# APM32F103xx register map
File version: 1.0
CPU: CM3 r2p1, little endian, no MPU, no FPU, 4 interrupt priority bits
Registers are 32-bit, read-write, reset 0x0 unless marked. A register's access mark holds for its fields unless they carry their own. Offsets are from the block's base; [hi:lo] are bit positions; {n}, {i} and the like mark numbered series; 'fields as' and 'values as' point back to an identical list.

## CRC — CRC calculation unit
Base 0x40023000
0x00 DATA reset 0xFFFFFFFF
0x04 INDATA — Independent Data register
  [7:0] INDATA
0x08 CTRL wo — Control register
  [0] RST — Reset bit

## FMC — Flash memory controller
Base 0x40022000
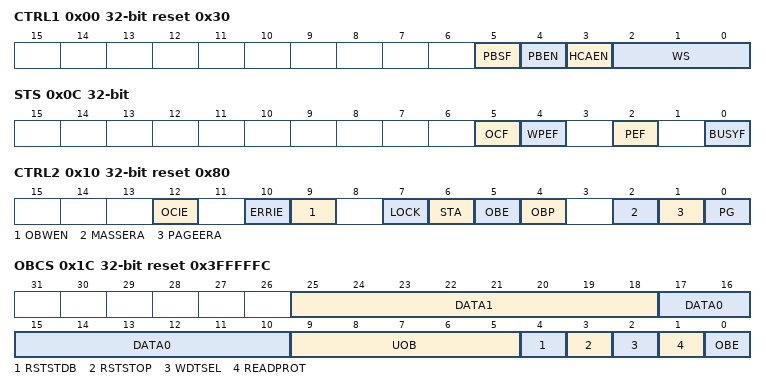
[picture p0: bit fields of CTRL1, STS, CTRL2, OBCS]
0x00 CTRL1 access per field reset 0x30 — Flash access control register
  [5] PBSF ro — Prefetch buffer status
  [4] PBEN rw — Prefetch buffer enable
  [3] HCAEN rw — Flash half cycle access enable
  [2:0] WS rw — Latency
0x04 KEY wo
  [31:0] KEY — FMC key
0x08 OBKEY wo — option byte key register
  [31:0] OBKEY — Option byte key
0x0C STS access per field — status register
  [5] OCF rw — End of operation
  [4] WPEF rw — Write protection error
  [2] PEF rw — Programming error
  [0] BUSYF ro — Busy
0x10 CTRL2 reset 0x80 — Control register
  [12] OCIE — End of operation interrupt enable
  [10] ERRIE — Error interrupt enable
  [9] OBWEN — Option bytes write enable
  [7] LOCK
  [6] STA — Start
  [5] OBE — Option byte erase
  [4] OBP — Option byte programming
  [2] MASSERA — Mass Erase
  [1] PAGEERA — Page Erase
  [0] PG — Programming
0x14 ADDR wo — Flash address register
  [31:0] ADDR — Flash Address
0x1C OBCS ro reset 0x3FFFFFC — Option byte register
  [25:18] DATA1
  [17:10] DATA0 — Data1
  [9:5] UOB
  [4] RSTSTDB — nRST_STDBY
  [3] RSTSTOP — nRST_STOP
  [2] WDTSEL
  [1] READPROT — Read protection
  [0] OBE — Option byte error
0x20 WRTPROT ro reset 0xFFFFFFFF — Write protection register
  [31:0] WRTPROT — Write protect

## DMA1 — DMA1 controller
Base 0x40020000
Same registers: DMA2 0x40020400
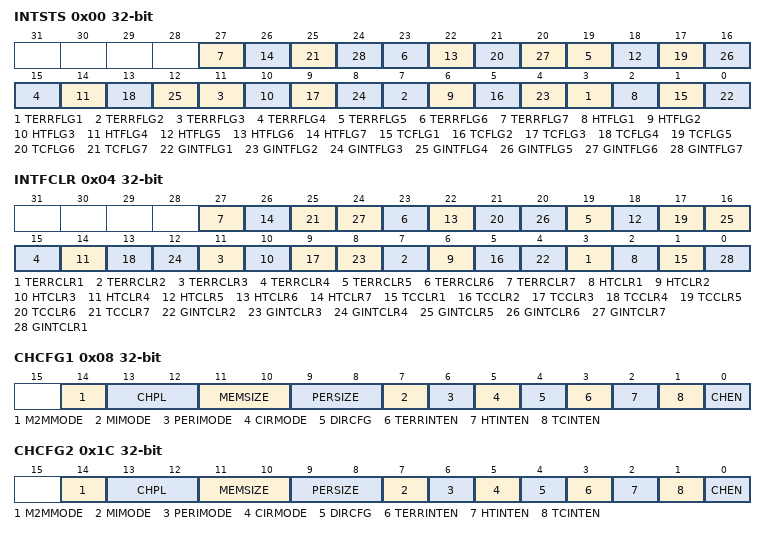
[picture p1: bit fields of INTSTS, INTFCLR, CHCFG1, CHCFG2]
0x00 INTSTS ro — DMA Interrupt status register (DMA_INTSTS)
  [4n-1] TERRFLG{n} (n=1..7) — Channel {n} Transfer Error flag
  [4n-2] HTFLG{n} (n=1..7) — Channel {n} Half Transfer Complete flag
  [4n-3] TCFLG{n} (n=1..7) — Channel {n} Transfer Complete flag
  [4n-4] GINTFLG{n} (n=1..7) — Channel {n} Global interrupt flag
0x04 INTFCLR wo — DMA Interrupt reset register (DMA_INTFCLR)
  [4n-1] TERRCLR{n} (n=1..7) — Channel {n} Transfer Error reset
  [4n-2] HTCLR{n} (n=1..7) — Channel {n} Half Transfer reset
  [4n-3] TCCLR{n} (n=1..7) — Channel {n} Transfer Complete reset
  [4n-4] GINTCLR{n} (n=2..7) — Channel {n} Global interrupt reset
  [0] GINTCLR1 — Channel 1 Global interrupt resetr
0x08 CHCFG1 — DMA channel 1 configuration register
  [14] M2MMODE — Memory to memory mode
  [13:12] CHPL — Channel Priority level
  [11:10] MEMSIZE — Memory size
  [9:8] PERSIZE — Peripheral size
  [7] MIMODE — Memory increment mode
  [6] PERIMODE — Peripheral increment mode
  [5] CIRMODE — Circular mode
  [4] DIRCFG — Data transfer direction
  [3] TERRINTEN — Transfer error interrupt enable
  [2] HTINTEN — Half Transfer interrupt enable
  [1] TCINTEN — Transfer complete interrupt enable
  [0] CHEN — Channel enable
0x0C CHNDATA1 — DMA channel 1 number of data register
  [15:0] NDATA — Number of data to transfer
0x10 CHPADDR1 — DMA channel 1 peripheral address register
  [31:0] PERADDR — Peripheral address
{0x0+0x14*i} CHMADDR{i} (i=1..7) — DMA channel {i} memory address register
  [31:0] MEMADDR — Memory address
0x1C CHCFG2 — DMA channel 2 configuration register
  fields as CHCFG1
0x20 CHNDATA2 — DMA channel 2 number of data register
  [15:0] NDATA — Number of data to transfer
0x24 CHPADDR2 — DMA channel 2 peripheral address register
  [31:0] PERADDR — Peripheral address
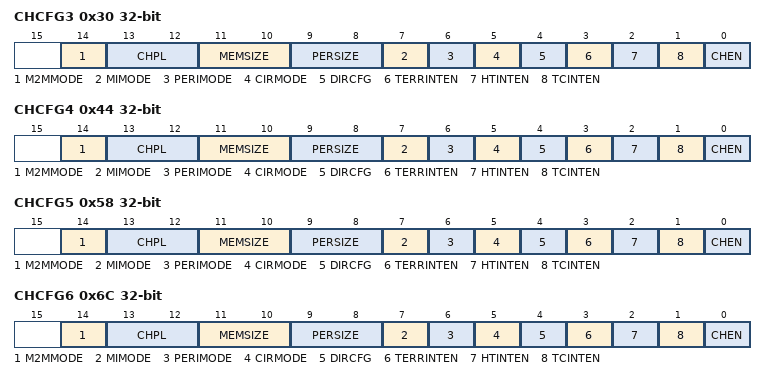
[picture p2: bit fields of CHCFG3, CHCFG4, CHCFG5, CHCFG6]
0x30 CHCFG3 — DMA channel 3 configuration register
  fields as CHCFG1
0x34 CHNDATA3 — DMA channel 3 number of data register
  [15:0] NDATA — Number of data to transfer
0x38 CHPADDR3 — DMA channel 3 peripheral address register
  [31:0] PERADDR — Peripheral address
0x44 CHCFG4 — DMA channel 4 configuration register
  fields as CHCFG1
0x48 CHNDATA4 — DMA channel 4 number of data register
  [15:0] NDATA — Number of data to transfer
0x4C CHPADDR4 — DMA channel 4 peripheral address register
  [31:0] PERADDR — Peripheral address
0x58 CHCFG5 — DMA channel 5 configuration register
  fields as CHCFG1
0x5C CHNDATA5 — DMA channel 5 number of data register
  [15:0] NDATA — Number of data to transfer
0x60 CHPADDR5 — DMA channel 5 peripheral address register
  [31:0] PERADDR — Peripheral address
0x6C CHCFG6 — DMA channel 6 configuration register
  fields as CHCFG1
0x70 CHNDATA6 — DMA channel 6 number of data register
  [15:0] NDATA — Number of data to transfer
0x74 CHPADDR6 — DMA channel 6 peripheral address register
  [31:0] PERADDR — Peripheral address
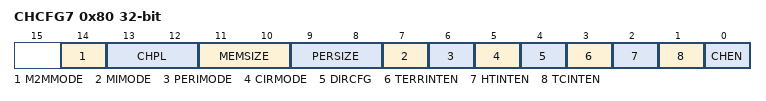
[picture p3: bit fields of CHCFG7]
0x80 CHCFG7 — DMA channel 7 configuration register
  fields as CHCFG1
0x84 CHNDATA7 — DMA channel 7 number of data register
  [15:0] NADDR — Number of data to transfer
0x88 CHPADDR7 — DMA channel 7 peripheral address register
  [31:0] PERADDR — Peripheral address
